# SKEAZ1284 register map
File version: 1.6
Registers are 8-bit, read-write, reset 0x0 unless marked. A register's access mark holds for its fields unless they carry their own. Offsets are from the block's base; [hi:lo] are bit positions; {n}, {i} and the like mark numbered series.

## SIM — System Integration Module
Base 0x40048000; register names take the prefix SIM_
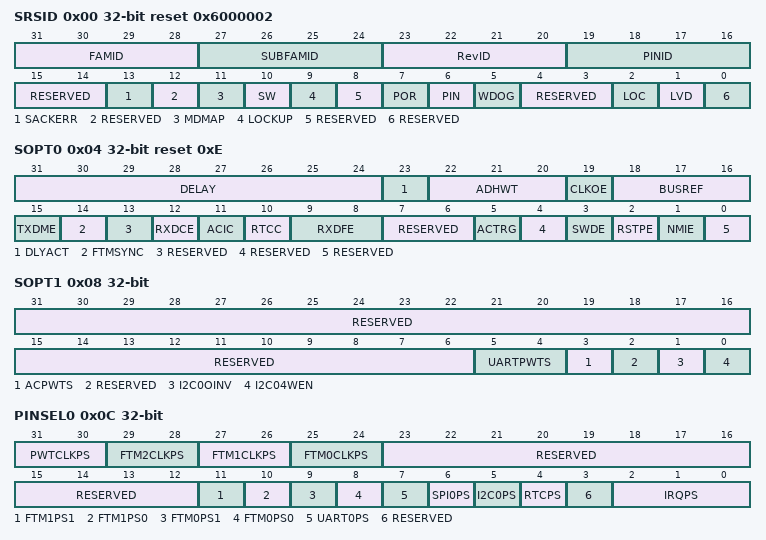
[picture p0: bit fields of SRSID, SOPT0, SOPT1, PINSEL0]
0x00 SRSID 32-bit ro reset 0x6000002 — System Reset Status and ID Register
  [31:28] FAMID — Kinetis family ID
    0=KE0x family
  [27:24] SUBFAMID — Kinetis sub-family ID
    4=KEx4 sub-family; 6=KEx6 sub-family
  [23:20] RevID — Device Revision Number
  [19:16] PINID — Device Pin ID
    0=8-pin; 1=16-pin; 2=20-pin; 3=24-pin; 4=32-pin; 5=44-pin; 6=48-pin; 7=64-pin; 8=80-pin; 10=100-pin
  [15:14] RESERVED
  [13] SACKERR — Stop Mode Acknowledge Error Reset
    0=Reset is not caused by peripheral failure to acknowledge attempt to enter Stop mode; 1=Reset is caused by peripheral failure to acknowledge attempt to enter Stop mode
  [12] RESERVED
  [11] MDMAP — MDM-AP System Reset Request
    0=Reset is not caused by host debugger system setting of the System Reset Request bit; 1=Reset is caused by host debugger system setting of the System Reset Request bit
  [10] SW — Software
    0=Reset is not caused by software setting of SYSRESETREQ bit; 1=Reset caused by software setting of SYSRESETREQ bit
  [9] LOCKUP — Core Lockup
    0=Reset is not caused by core LOCKUP event; 1=Reset is caused by core LOCKUP event
  [8] RESERVED
  [7] POR — Power-On Reset
    0=Reset not caused by POR; 1=POR caused reset
  [6] PIN — External Reset Pin
    0=Reset is not caused by external reset pin; 1=Reset came from external reset pin
  [5] WDOG — Watchdog (WDOG)
    0=Reset is not caused by WDOG timeout; 1=Reset is caused by WDOG timeout
  [4:3] RESERVED
  [2] LOC — Internal Clock Source Module Reset
    0=Reset is not caused by the ICS module; 1=Reset is caused by the ICS module
  [1] LVD — Low Voltage Detect
    0=Reset is not caused by LVD trip or POR; 1=Reset is caused by LVD trip or POR
  [0] RESERVED
0x04 SOPT0 32-bit reset 0xE — System Options Register 0
  [31:24] DELAY — FTM2 Trigger Delay
  [23] DLYACT ro — FTM2 Trigger Delay Active
    0=The delay is inactive; 1=The delay is active
  [22:20] ADHWT — ADC Hardware Trigger Source
    0=RTC overflow as the ADC hardware trigger; 1=FTM0 as the ADC hardware trigger; 2=FTM2 init trigger with 8-bit programmable counter delay; 3=FTM2 match trigger with 8-bit programmable counter delay; 4=PIT channel0 overflow as the ADC hardware trigger; 5=PIT channel1 overflow as the ADC hardware trigger; 6=ACMP0 out as the ADC hardware trigger; 7=ACMP1 out as the ADC hardware trigger
  [19] CLKOE — Bus Clock Output Enable
    0=Bus clock output is disabled on PTH2; 1=Bus clock output is enabled on PTH2
  [18:16] BUSREF — BUS Clock Output select
    0=Bus; 1=Bus divided by 2; 2=Bus divided by 4; 3=Bus divided by 8; 4=Bus divided by 16; 5=Bus divided by 32; 6=Bus divided by 64; 7=Bus divided by 128
  [15] TXDME — UART0_TX Modulation Select
    0=UART0_TX output is connected to pinout directly; 1=UART0_TX output is modulated by FTM0 channel 0 before mapped to pinout
  [14] FTMSYNC wo — FTM2 Synchronization Select
    0=No synchronization triggered; 1=Generates a PWM synchronization trigger to the FTM2 modules
  [13] RESERVED ro
  [12] RXDCE — UART0_RX Capture Select
    0=UART0_RX input signal is connected to the UART0 module only; 1=UART0_RX input signal is connected to the UART0 module and FTM0 channel 1
  [11] ACIC — Analog Comparator to Input Capture Enable
    0=ACMP0 output is not connected to FTM1 input channel 0; 1=ACMP0 output is connected to FTM1 input channel 0
  [10] RTCC — Real-Time Counter Capture
    0=RTC overflow is not connected to FTM1 input channel 1; 1=RTC overflow is connected to FTM1 input channel 1
  [9:8] RXDFE — UART0 RxD Filter Select
    0=RXD0 input signal is connected to UART0 module directly; 1=RXD0 input signal is filtered by ACMP0, then injected to UART0; 2=RXD0 input signal is filtered by ACMP1, then injected to UART0
  [7:6] RESERVED ro
  [5] ACTRG — ACMP Trigger FTM2 selection
    0=ACMP0 out; 1=ACMP1 out
  [4] RESERVED ro
  [3] SWDE — Single Wire Debug Port Pin Enable
    0=PTA4/KBI0_P4/ACMP0_OUT/SWD_DIO as PTA4 or ACMP0_OUT function, PTC4/KBI0_P20/RTC_CLKOUT/FTM1_CH0/ACMP0_IN2/SWD_CLK as PTC4, KBI0_P20, RTC_CLKOUT, FTM1_CH0, OR ACMP0_IN2 function; 1=PTA4/KBI0_P4/ACMP0_OUT/SWD_DIO as SWD_DIO function, PTC4/KBI0_P20/RTC_CLKOUT/FTM1_CH0/ACMP0_IN2/SWD_CLK as SWD_CLK function
  [2] RSTPE — RESET Pin Enable
    0=PTA5/KBI0_P5/IRQ/TCLK0/RESET pin functions as PTA5/KBI0_P5/IRQ/TCLK0; 1=PTA5/KBI0_P5/IRQ/TCLK0/RESET pin functions as RESET
  [1] NMIE — NMI Pin Enable
    0=PTB4/KBI0_P12/FTM2_CH4/SPI0_MISO/ACMP1_IN2/NMI pin functions as PTB4, KBI0_P12, FTM2_CH4, SPI0_MISO or ACMP1_IN2; 1=PTB4/KBI0_P12/FTM2_CH4/SPI0_MISO/ACMP1_IN2/NMI pin functions as NMI
  [0] RESERVED ro
0x08 SOPT1 32-bit — System Options Register
  [31:6] RESERVED ro
  [5:4] UARTPWTS — PWT UART RX select
    0=UART0 RX is connectted to PWTIN3; 1=UART1 RX is connectted to PWTIN3; 2=UART2 RX is connectted to PWTIN3
  [3] ACPWTS — PWT ACMP_OUT select
    0=ACMP0_OUT is connectted to PWTIN2; 1=ACMP1_OUT is connectted to PWTIN2
  [2] RESERVED ro
  [1] I2C0OINV — I2C0 Output Invert
    0=Under I2C0 4-wire interface configuration, SDA_OUT and SCL_OUT are not inverted before output; 1=Under I2C0 4-wire interface configuration, SDA_OUT and SCL_OUT are inverted before output
  [0] I2C04WEN — I2C0 4-Wire Interface Enable
    0=I2C0 4-wire interface configuration is disabled; 1=I2C0 4-wire interface configuration is enabled
0x0C PINSEL0 32-bit — Pin Selection Register 0
  [31:30] PWTCLKPS — PWT TCLK Pin Select
    0=Selects TCLK0 for PWT module; 1=Selects TCLK1 for PWT module; 2=Selects TCLK2 for PWT module
  [29:28] FTM2CLKPS — FTM2 TCLK Pin Select
    0=Selects TCLK0 for FTM2 module; 1=Selects TCLK1 for FTM2 module; 2=Selects TCLK2 for FTM2 module
  [27:26] FTM1CLKPS — FTM1 TCLK Pin Select
    0=Selects TCLK0 for FTM1 module; 1=Selects TCLK1 for FTM1 module; 2=Selects TCLK2 for FTM1 module
  [25:24] FTM0CLKPS — FTM0 TCLK Pin Select
    0=Selects TCLK0 for FTM0 module; 1=Selects TCLK1 for FTM0 module; 2=Selects TCLK2 for FTM0 module
  [23:12] RESERVED ro
  [11] FTM1PS1 — FTM1_CH1 Port Pin Select
    0=FTM1_CH1 channels are mapped on PTC5; 1=FTM1_CH1 channels are mapped on PTE7
  [10] FTM1PS0 — FTM1_CH0 Port Pin Select
    0=FTM1_CH0 channels are mapped on PTC4; 1=FTM1_CH0 channels are mapped on PTH2
  [9] FTM0PS1 — FTM0_CH1 Port Pin Select
    0=FTM0_CH1 channels are mapped on PTA1; 1=FTM0_CH1 channels are mapped on PTB3
  [8] FTM0PS0 — FTM0_CH0 Port Pin Select
    0=FTM0_CH0 channels are mapped on PTA0; 1=FTM0_CH0 channels are mapped on PTB2
  [7] UART0PS — UART0 Pin Select
    0=UART0_RX and UART0_TX are mapped on PTB0 and PTB1; 1=UART0_RX and UART0_TX are mapped on PTA2 and PTA3
  [6] SPI0PS — SPI0 Pin Select
    0=SPI0_SCK, SPI0_MOSI, SPI0_MISO, and SPI0_PCS are mapped on PTB2, PTB3, PTB4, and PTB5; 1=SPI0_SCK, SPI0_MOSI, SPI0_MISO, and SPI0_PCS are mapped on PTE0, PTE1, PTE2, and PTE3
  [5] I2C0PS — I2C0 Port Pin Select
    0=I2C0_SCL and I2C0_SDA are mapped on PTA3 and PTA2, respectively; 1=I2C0_SCL and I2C0_SDA are mapped on PTB7 and PTB6, respectively
  [4] RTCPS — RTCO Pin Select
    0=RTCO is mapped on PTC4; 1=RTCO is mapped on PTC5
  [3] RESERVED ro
  [2:0] IRQPS — IRQ Port Pin Select
    0=IRQ is mapped on PTA5; {v}=IRQ is mapped on PTI{v-1} (v=1..7)
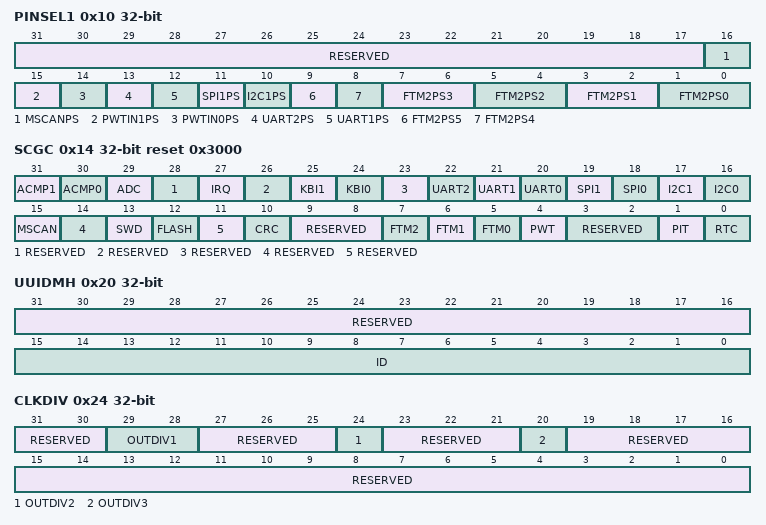
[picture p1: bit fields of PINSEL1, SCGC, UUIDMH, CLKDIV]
0x10 PINSEL1 32-bit — Pin Selection Register 1
  [31:17] RESERVED ro
  [16] MSCANPS — MSCAN Pin Select
    0=CAN_TX on PTC7, CAN_RX on PTC6; 1=CAN_TX on PTE7, CAN_RX on PTH2
  [15] PWTIN1PS — PWTIN1 Pin Select
    0=PWTIN1 on PTB0; 1=PWTIN1 on PTH7
  [14] PWTIN0PS — PWTIN0 Pin Select
    0=PWTIN0 on PTD5; 1=PWTIN0 on PTE2
  [13] UART2PS — UART2 Pin Select
    0=UART2_TX on PTD7, UART2_RX on PTD6; 1=UART2_TX on PTI1, UART2_RX on PTI0
  [12] UART1PS — UART1 Pin Select
    0=UART1_TX on PTC7, UART1_RX on PTC6; 1=UART1_TX on PTF3, UART1_RX on PTF2
  [11] SPI1PS — SPI1 Pin Select
    0=SPI1_SCK, SPI1_MOSI, SPI1_MISO, and SPI1_PCS are mapped on PTD0, PTD1, PTD2, and PTD3; 1=SPI1_SCK, SPI1_MOSI, SPI1_MISO, and SPI1_PCS are mapped on PTG4, PTG5, PTG6, and PTG7
  [10] I2C1PS — I2C1 Pin Select
    0=I2C1_SCL on PTE1, I2C1_SDA on PTE0; 1=I2C1_SCL on PTH4, I2C1_SDA on PTH3
  [9] FTM2PS5 — FTM2 Channel 5 Pin Select
    0=FTM2 CH5 mapped on PTB5; 1=FTM2 CH5 mapped on PTG7
  [8] FTM2PS4 — FTM2 Channel4 Pin Select
    0=FTM2 CH4 mapped on PTB4; 1=FTM2 CH4 mapped on PTG6
  [7:6] FTM2PS3 — FTM2 Channel 3 Pin Select
    0=FTM2 CH3 mapped on PTC3; 1=FTM2 CH3 mapped on PTD1; 2=FTM2 CH3 mapped on PTG5
  [5:4] FTM2PS2 — FTM2 Channel 2 Pin Select
    0=FTM2 CH2 mapped on PTC2; 1=FTM2 CH2 mapped on PTD0; 2=FTM2 CH2 mapped on PTG4
  [3:2] FTM2PS1 — FTM2 Channel 1 Pin Select
    0=FTM2 CH1 mapped on PTC1; 1=FTM2 CH1 mapped on PTH1; 2=FTM2 CH1 mapped on PTF1
  [1:0] FTM2PS0 — FTM2 Channel 0 Pin Select
    0=FTM2 CH0 mapped on PTC0; 1=FTM2 CH0 mapped on PTH0; 2=FTM2 CH0 mapped on PTF0
0x14 SCGC 32-bit reset 0x3000 — System Clock Gating Control Register
  [31] ACMP1 — ACMP1 Clock Gate Control
    0=Bus clock to the ACMP1 module is disabled; 1=Bus clock to the ACMP1 module is enabled
  [30] ACMP0 — ACMP0 Clock Gate Control
    0=Bus clock to the ACMP0 module is disabled; 1=Bus clock to the ACMP0 module is enabled
  [29] ADC — ADC Clock Gate Control
    0=Bus clock to the ADC module is disabled; 1=Bus clock to the ADC module is enabled
  [28] RESERVED ro
  [27] IRQ — IRQ Clock Gate Control
    0=Bus clock to the IRQ module is disabled; 1=Bus clock to the IRQ module is enabled
  [26] RESERVED ro
  [25] KBI1 — KBI1 Clock Gate Control
    0=Bus clock to the KBI1 module is disabled; 1=Bus clock to the KBI1 module is enabled
  [24] KBI0 — KBI0 Clock Gate Control
    0=Bus clock to the KBI0 module is disabled; 1=Bus clock to the KBI0 module is enabled
  [23] RESERVED ro
  [22] UART2 — UART2 Clock Gate Control
    0=Bus clock to the UART2 module is disabled; 1=Bus clock to the UART2 module is enabled
  [21] UART1 — UART1 Clock Gate Control
    0=Bus clock to the UART1 module is disabled; 1=Bus clock to the UART1 module is enabled
  [20] UART0 — UART0 Clock Gate Control
    0=Bus clock to the UART0 module is disabled; 1=Bus clock to the UART0 module is enabled
  [19] SPI1 — SPI1 Clock Gate Control
    0=Bus clock to the SPI1 module is disabled; 1=Bus clock to the SPI1 module is enabled
  [18] SPI0 — SPI0 Clock Gate Control
    0=Bus clock to the SPI0 module is disabled; 1=Bus clock to the SPI0 module is enabled
  [17] I2C1 — I2C1 Clock Gate Control
    0=Bus clock to the I2C1 module is disabled; 1=Bus clock to the I2C1 module is enabled
  [16] I2C0 — I2C0 Clock Gate Control
    0=Bus clock to the I2C0 module is disabled; 1=Bus clock to the I2C0 module is enabled
  [15] MSCAN — MSCAN Clock Gate Control
    0=Bus clock to the MSCAN module is disabled; 1=Bus clock to the MSCAN module is enabled
  [14] RESERVED ro
  [13] SWD — SWD (single wire debugger) Clock Gate Control
    0=Bus clock to the SWD module is disabled; 1=Bus clock to the SWD module is enabled
  [12] FLASH — Flash Clock Gate Control
    0=Bus clock to the flash module is disabled; 1=Bus clock to the flash module is enabled
  [11] RESERVED ro
  [10] CRC — CRC Clock Gate Control
    0=Bus clock to the CRC module is disabled; 1=Bus clock to the CRC module is enabled
  [9:8] RESERVED ro
  [7] FTM2 — FTM2 Clock Gate Control
    0=Bus clock to the FTM2 module is disabled; 1=Bus clock to the FTM2 module is enabled
  [6] FTM1 — FTM1 Clock Gate Control
    0=Bus clock to the FTM1 module is disabled; 1=Bus clock to the FTM1 module is enabled
  [5] FTM0 — FTM0 Clock Gate Control
    0=Bus clock to the FTM0 module is disabled; 1=Bus clock to the FTM0 module is enabled
  [4] PWT — PWT Clock Gate Control
    0=Timer clock to the PWT module is disabled; 1=Timer clock to the PWT module is enabled
  [3:2] RESERVED ro
  [1] PIT — PIT Clock Gate Control
    0=Bus clock to the PIT module is disabled; 1=Bus clock to the PIT module is enabled
  [0] RTC — RTC Clock Gate Control
    0=Bus clock to the RTC module is disabled; 1=Bus clock to the RTC module is enabled
0x18 UUIDL 32-bit ro reset not defined — Universally Unique Identifier Low Register
  [31:0] ID — Universally Unique Identifier
0x1C UUIDML 32-bit ro reset not defined — Universally Unique Identifier Middle Low Register
  [31:0] ID — Universally Unique Identifier
0x20 UUIDMH 32-bit ro reset not defined — Universally Unique Identifier Middle High Register
  [31:16] RESERVED
  [15:0] ID — Universally Unique Identifier
0x24 CLKDIV 32-bit — Clock Divider Register
  [31:30] RESERVED ro
  [29:28] OUTDIV1 — Clock 1 output divider value
    0=Same as ICSOUTCLK; 1=ICSOUTCLK divides by 2; 2=ICSOUTCLK divides by 3; 3=ICSOUTCLK divides by 4
  [27:25] RESERVED ro
  [24] OUTDIV2 — Clock 2 output divider value
    0=Not divided from divider1; 1=Divide by 2 from divider1
  [23:21] RESERVED ro
  [20] OUTDIV3 — Clock 3 output divider value
    0=Same as ICSOUTCLK; 1=ICSOUTCLK divides by 2
  [19:0] RESERVED ro
